# MSP432E401Y register map
Vendor: Texas Instruments; File version: 3.200
CPU: CM4 r1p2, little endian, no MPU, no FPU, 0x3 interrupt priority bits, 0x0 interrupts
Registers are 32-bit, read-write, no defined reset value unless marked. A register's access mark holds for its fields unless they carry their own. Offsets are from the block's base; [hi:lo] are bit positions; {n}, {i} and the like mark numbered series.

## SHAMD5 — Register map for SHAMD5 peripheral
Base 0x44034000; register names take the prefix SHAMD5
0x00 ODIGEST_A — SHA Outer Digest A
  [31:0] SHAMD5_ODIGEST_A_DATA — Digest/Key Data
0x04 ODIGEST_B — SHA Outer Digest B
  [31:0] SHAMD5_ODIGEST_B_DATA — Digest/Key Data
0x08 ODIGEST_C — SHA Outer Digest C
  [31:0] SHAMD5_ODIGEST_C_DATA — Digest/Key Data
0x0C ODIGEST_D — SHA Outer Digest D
  [31:0] SHAMD5_ODIGEST_D_DATA — Digest/Key Data
0x10 ODIGEST_E — SHA Outer Digest E
  [31:0] SHAMD5_ODIGEST_E_DATA — Digest/Key Data
0x14 ODIGEST_F — SHA Outer Digest F
  [31:0] SHAMD5_ODIGEST_F_DATA — Digest/Key Data
0x18 ODIGEST_G — SHA Outer Digest G
  [31:0] SHAMD5_ODIGEST_G_DATA — Digest/Key Data
0x1C ODIGEST_H — SHA Outer Digest H
  [31:0] SHAMD5_ODIGEST_H_DATA — Digest/Key Data
0x20 IDIGEST_A — SHA Inner Digest A
  [31:0] SHAMD5_IDIGEST_A_DATA — Digest/Key Data
0x24 IDIGEST_B — SHA Inner Digest B
  [31:0] SHAMD5_IDIGEST_B_DATA — Digest/Key Data
0x28 IDIGEST_C — SHA Inner Digest C
  [31:0] SHAMD5_IDIGEST_C_DATA — Digest/Key Data
0x2C IDIGEST_D — SHA Inner Digest D
  [31:0] SHAMD5_IDIGEST_D_DATA — Digest/Key Data
0x30 IDIGEST_E — SHA Inner Digest E
  [31:0] SHAMD5_IDIGEST_E_DATA — Digest/Key Data
0x34 IDIGEST_F — SHA Inner Digest F
  [31:0] SHAMD5_IDIGEST_F_DATA — Digest/Key Data
0x38 IDIGEST_G — SHA Inner Digest G
  [31:0] SHAMD5_IDIGEST_G_DATA — Digest/Key Data
0x3C IDIGEST_H — SHA Inner Digest H
  [31:0] SHAMD5_IDIGEST_H_DATA — Digest/Key Data
0x40 DIGEST_COUNT — SHA Digest Count
  [31:0] SHAMD5_DIGEST_COUNT — Digest Count
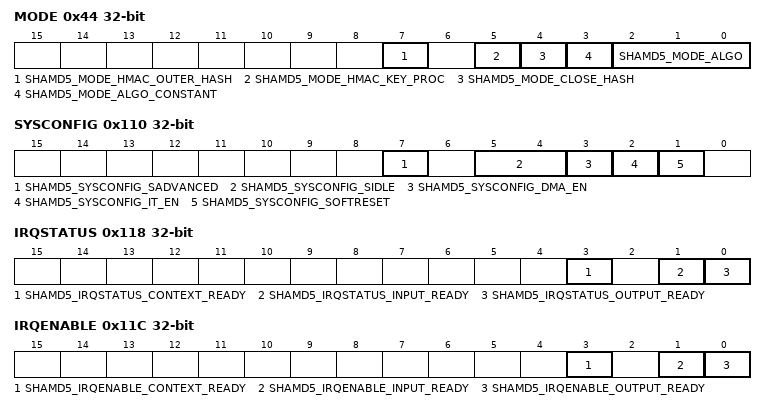
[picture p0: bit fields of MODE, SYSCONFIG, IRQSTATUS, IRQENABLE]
0x44 MODE — SHA Mode
  [7] SHAMD5_MODE_HMAC_OUTER_HASH — HMAC Outer Hash Processing Enable
  [5] SHAMD5_MODE_HMAC_KEY_PROC — HMAC Key Processing Enable
  [4] SHAMD5_MODE_CLOSE_HASH — Performs the padding, the Hash/HMAC will be 'closed' at the end of the block, as per MD5/SHA-1/SHA-2 specification
  [3] SHAMD5_MODE_ALGO_CONSTANT — The initial digest register will be overwritten with the algorithm constants for the selected algorithm when hashing and the initial digest count register will be reset to 0
  [2:0] SHAMD5_MODE_ALGO — Hash Algorithm
    0=SHAMD5_MODE_ALGO_MD5 (MD5); 2=SHAMD5_MODE_ALGO_SHA1 (SHA-1); 4=SHAMD5_MODE_ALGO_SHA224 (SHA-224); 6=SHAMD5_MODE_ALGO_SHA256 (SHA-256)
0x48 LENGTH — SHA Length
  [31:0] SHAMD5_LENGTH — Block Length/Remaining Byte Count
{0x80+4i} DATA_{i}_IN (i=0..15) — SHA Data {i} Input
  [31:0] SHAMD5_DATA_{i}_IN_DATA — Digest/Key Data
0x100 REVISION — SHA Revision
  [31:0] SHAMD5_REVISION — Revision Number
0x110 SYSCONFIG — SHA System Configuration
  [7] SHAMD5_SYSCONFIG_SADVANCED — Advanced Mode Enable
  [5:4] SHAMD5_SYSCONFIG_SIDLE — Sidle mode
    0=SHAMD5_SYSCONFIG_SIDLE_FORCE (Force-idle mode)
  [3] SHAMD5_SYSCONFIG_DMA_EN — uDMA Request Enable
  [2] SHAMD5_SYSCONFIG_IT_EN — Interrupt Enable
  [1] SHAMD5_SYSCONFIG_SOFTRESET — Soft reset
0x114 SYSSTATUS — SHA System Status
  [0] SHAMD5_SYSSTATUS_RESETDONE — Reset done status
0x118 IRQSTATUS — SHA Interrupt Status
  [3] SHAMD5_IRQSTATUS_CONTEXT_READY — Context Ready Status
  [1] SHAMD5_IRQSTATUS_INPUT_READY — Input Ready Status
  [0] SHAMD5_IRQSTATUS_OUTPUT_READY — Output Ready Status
0x11C IRQENABLE — SHA Interrupt Enable
  [3] SHAMD5_IRQENABLE_CONTEXT_READY — Mask for context ready interrupt
  [1] SHAMD5_IRQENABLE_INPUT_READY — Mask for input ready interrupt
  [0] SHAMD5_IRQENABLE_OUTPUT_READY — Mask for output ready interrupt

## SHAMD5_DMA — Register map for SHAMD5 DMA peripheral
Base 0x44030010; register names take the prefix SHAMD5_DMA
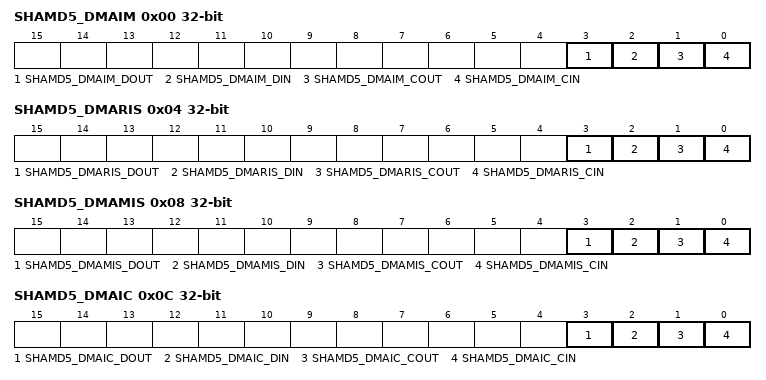
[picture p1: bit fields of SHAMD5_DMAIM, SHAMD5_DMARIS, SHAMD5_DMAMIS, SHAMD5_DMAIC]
0x00 SHAMD5_DMAIM — SHAMD5 DMA Interrupt Mask
  [3] SHAMD5_DMAIM_DOUT — Data Out DMA Done Interrupt Mask
  [2] SHAMD5_DMAIM_DIN — Data In DMA Done Interrupt Mask
  [1] SHAMD5_DMAIM_COUT — Context Out DMA Done Interrupt Mask
  [0] SHAMD5_DMAIM_CIN — Context In DMA Done Interrupt Mask
0x04 SHAMD5_DMARIS — SHAMD5 DMA Raw Interrupt Status
  [3] SHAMD5_DMARIS_DOUT — Data Out DMA Done Raw Interrupt Status
  [2] SHAMD5_DMARIS_DIN — Data In DMA Done Raw Interrupt Status
  [1] SHAMD5_DMARIS_COUT — Context Out DMA Done Raw Interrupt Status
  [0] SHAMD5_DMARIS_CIN — Context In DMA Done Raw Interrupt Status
0x08 SHAMD5_DMAMIS — SHAMD5 DMA Masked Interrupt Status
  [3] SHAMD5_DMAMIS_DOUT — Data Out DMA Done Masked Interrupt Status
  [2] SHAMD5_DMAMIS_DIN — Data In DMA Done Masked Interrupt Status
  [1] SHAMD5_DMAMIS_COUT — Context Out DMA Done Masked Interrupt Status
  [0] SHAMD5_DMAMIS_CIN — Context In DMA Done Masked Interrupt Status
0x0C SHAMD5_DMAIC — SHAMD5 DMA Interrupt Clear
  [3] SHAMD5_DMAIC_DOUT — Data Out DMA Done Interrupt Clear
  [2] SHAMD5_DMAIC_DIN — Data In DMA Done Interrupt Clear
  [1] SHAMD5_DMAIC_COUT — Context Out DMA Done Interrupt Clear
  [0] SHAMD5_DMAIC_CIN — Context In DMA Done Interrupt Clear
